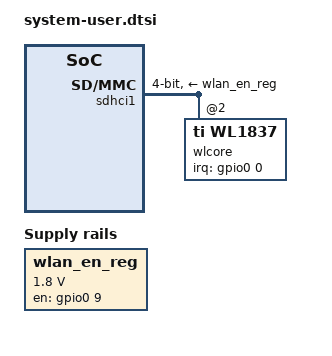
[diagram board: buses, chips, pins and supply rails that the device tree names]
#include <dt-bindings/gpio/gpio.h>
#include <dt-bindings/interrupt-controller/irq.h>

/include/ "system-conf.dtsi"
/ {
	wlan_en_reg: fixedregulator@2 {
		compatible = "regulator-fixed";
		regulator-name = "wlan-en-regulator";
		regulator-min-microvolt = <1800000>;
		regulator-max-microvolt = <1800000>;
		startup-delay-us = <70000>;

		/* WLAN_EN GPIO for this board - Bank1, pin16 */
		gpio = <&gpio0 9 GPIO_ACTIVE_HIGH>;
		enable-active-high;
	};
};

&sdhci1 {
	/* Wi-Fi */
	vmmc-supply = <&wlan_en_reg>;
	bus-width = <4>;
	cap-power-off-card;
	keep-power-in-suspend;
	#address-cells = <1>;
	#size-cells = <0>;

	wlcore: wlcore@2 {
		compatible = "ti,wl1837";
		reg = <2>;
		interrupt-parent = <&gpio0>;
		interrupts = <0 IRQ_TYPE_LEVEL_HIGH>;
	};
};
